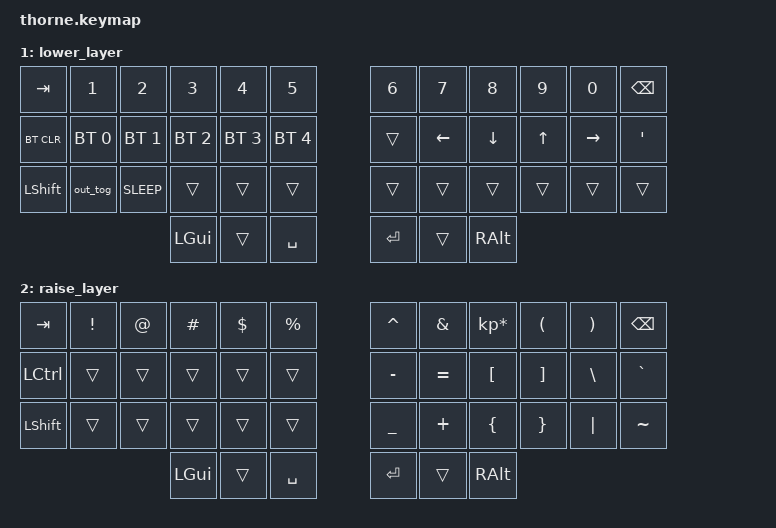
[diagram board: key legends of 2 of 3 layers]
#include <behaviors.dtsi>
#include <dt-bindings/zmk/keys.h>
#include <dt-bindings/zmk/bt.h>
#include <dt-bindings/zmk/ext_power.h>
#include <dt-bindings/zmk/outputs.h>

#define DEFAULT 0
#define LOWER   1
#define RAISE   2
#define ADJUST  3

/ {
    conditional_layers {
        compatible = "zmk,conditional-layers";
        tri_layer {
            if-layers = <LOWER RAISE>;
            then-layer = <ADJUST>;
        };
    };

        keymap {
                compatible = "zmk,keymap";

                default_layer {
// -----------------------------------------------------------------------------------------
// |  TAB |  Q  |  W  |  E  |  R  |  T  |   |  Y  |  U   |  I  |  O  |  P  | BKSP |
// | CTRL |  A  |  S  |  D  |  F  |  G  |   |  H  |  J   |  K  |  L  |  ;  |ENTER |
// | SHFT |  Z  |  X  |  C  |  V  |  B  |   |  N  |  M   |  ,  |  .  |  /  | ESC  |
//                    | ALT | LWR | SPC |   | SPC | RSE  | GUI |
                        bindings = <
   &kp TAB   &kp Q &kp W &kp E &kp R &kp T   &kp Y &kp U  &kp I     &kp O   &kp P    &kp BSPC
   &kp LCTRL &kp A &kp S &kp D &kp F &kp G   &kp H &kp J  &kp K     &kp L   &kp SEMI &kp RET
   &kp LSHFT &kp Z &kp X &kp C &kp V &kp B   &kp N &kp M  &kp COMMA &kp DOT &kp FSLH &kp ESC
                  &kp LALT &mo 1 &kp SPACE   SPACE RET &mo 2 &kp LGUI
                        >;
                };
                lower_layer {
// -----------------------------------------------------------------------------------------
// |  TAB |  1  |  2  |  3  |  4  |  5  |   |  6  |  7  |  8  |  9  |  0  | BKSP |
// | BTCLR| BT1 | BT2 | BT3 | BT4 | BT5 |   |     | LFT | DWN |  UP | RGT |  '   |
// | SHFT | OT  | SLP |     |     |     |   |     |     |     |     |     |      |
//                    | GUI |     | SPC |   | ENT |     | ALT |
                        bindings = <
   &kp TAB    &kp N1       &kp N2       &kp N3       &kp N4       &kp N5         &kp N6   &kp N7   &kp N8 &kp N9    &kp N0 &kp BSPC
   &bt BT_CLR &bt BT_SEL 0 &bt BT_SEL 1 &bt BT_SEL 2 &bt BT_SEL 3 &bt BT_SEL 4   &trans &kp LEFT &kp DOWN &kp UP &kp RIGHT &kp SQT
   &kp LSHFT  &out_tog    &kp K_SLEEP   &trans       &trans       &trans         &trans   &trans   &trans &trans    &trans &trans
                          	        &kp LGUI     &trans       &kp SPACE      &kp RET  &trans   &kp RALT
                        >;
                };

                raise_layer {
// -----------------------------------------------------------------------------------------
// |  TAB |  !  |  @  |  #  |  $  |  %  |   |  ^  |  &  |  *  |  (  |  )  | BKSP |
// | CTRL |     |     |     |     |     |   |  -  |  =  |  [  |  ]  |  \  |  `   |
// | SHFT |     |     |     |     |     |   |  _  |  +  |  {  |  }  | "|" |  ~   |
//                    | GUI |     | SPC |   | ENT |     | ALT |
                        bindings = <
   &kp  TAB  &kp EXCL &kp AT &kp HASH &kp DLLR &kp PRCNT   &kp CARET &kp AMPS  &kp KP_MULTIPLY &kp LPAR &kp RPAR &kp BSPC
   &kp LCTRL &trans   &trans &trans   &trans   &trans      &kp MINUS &kp EQUAL &kp LBKT        &kp RBKT &kp BSLH &kp GRAVE
   &kp LSHFT &trans   &trans &trans   &trans   &trans      &kp UNDER &kp PLUS  &kp LBRC        &kp RBRC &kp PIPE &kp TILDE
                    	     &kp LGUI &trans   &kp SPACE   &kp RET   &trans    &kp RALT
                        >;
                };

                 adjust_layer {
// -----------------------------------------------------------------------------------------
// |  TAB |     |     |     |     |     |   |     |     |     |     |     | BKSP |
// | CTRL |     |     |     |     |     |   |     |     |     |     |     |  `   |
// | SHFT |     |     |     |     |     |   |     |     |     |     |     |      |
//                    | GUI |     | SPC |   | ENT |     |     |
                        bindings = <
   &kp  TAB  &trans   &trans &trans   &trans   &trans      &trans &trans  &trans       &trans &trans &kp BSPC
   &kp LCTRL &trans   &trans &trans   &trans   &trans      &trans &transL &trans       &trans &trans &trans
   &kp LSHFT &trans   &trans &trans   &trans   &trans      &trans &trans  &trans       &trans &trans &trans
                    	     &kp LGUI &trans   &kp SPACE   &kp RET   &trans    &kp RALT
        
        };
}; 
